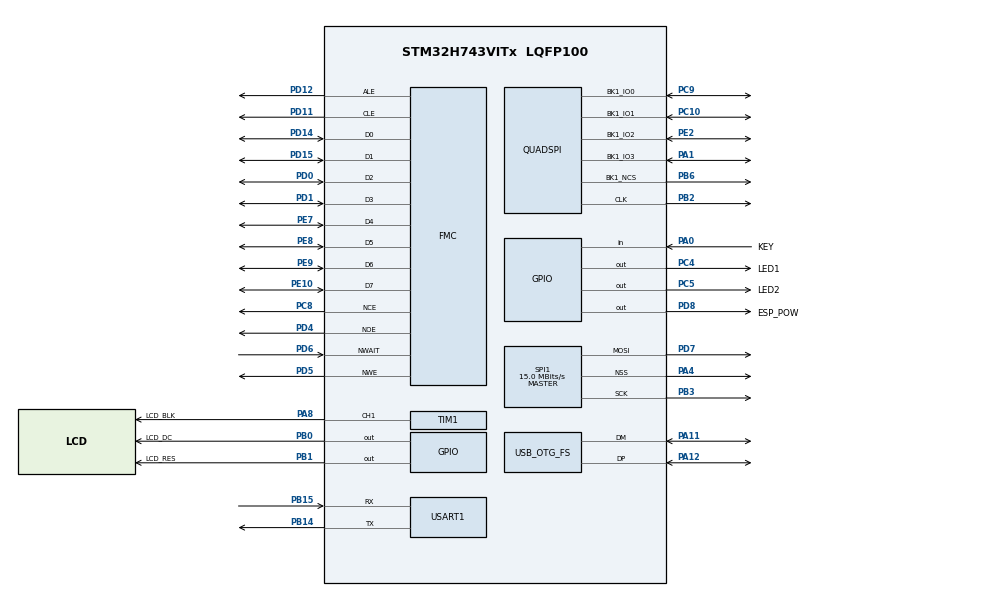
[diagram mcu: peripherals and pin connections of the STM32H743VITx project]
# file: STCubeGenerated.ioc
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CRC.InputDataFormat=CRC_INPUTDATA_FORMAT_WORDS
Dma.Request0=USART1_RX
Dma.Request1=USART1_TX
Dma.Request2=SPI1_TX
Dma.SPI1_TX.2.Direction=DMA_MEMORY_TO_PERIPH
Dma.SPI1_TX.2.EventEnable=DISABLE
Dma.SPI1_TX.2.FIFOMode=DMA_FIFOMODE_DISABLE
Dma.SPI1_TX.2.Instance=DMA1_Stream0
Dma.SPI1_TX.2.MemDataAlignment=DMA_MDATAALIGN_HALFWORD
Dma.SPI1_TX.2.MemInc=DMA_MINC_ENABLE
Dma.SPI1_TX.2.Mode=DMA_NORMAL
Dma.SPI1_TX.2.PeriphDataAlignment=DMA_PDATAALIGN_HALFWORD
Dma.SPI1_TX.2.PeriphInc=DMA_PINC_DISABLE
Dma.SPI1_TX.2.Polarity=HAL_DMAMUX_REQ_GEN_RISING
Dma.SPI1_TX.2.Priority=DMA_PRIORITY_LOW
Dma.SPI1_TX.2.RequestNumber=1
Dma.SPI1_TX.2.SignalID=NONE
Dma.SPI1_TX.2.SyncEnable=DISABLE
Dma.SPI1_TX.2.SyncPolarity=HAL_DMAMUX_SYNC_NO_EVENT
Dma.SPI1_TX.2.SyncRequestNumber=1
Dma.SPI1_TX.2.SyncSignalID=NONE
Dma.USART1_RX.0.Direction=DMA_PERIPH_TO_MEMORY
Dma.USART1_RX.0.EventEnable=DISABLE
Dma.USART1_RX.0.FIFOMode=DMA_FIFOMODE_DISABLE
Dma.USART1_RX.0.Instance=DMA1_Stream2
Dma.USART1_RX.0.MemDataAlignment=DMA_MDATAALIGN_BYTE
Dma.USART1_RX.0.MemInc=DMA_MINC_ENABLE
Dma.USART1_RX.0.Mode=DMA_CIRCULAR
Dma.USART1_RX.0.PeriphDataAlignment=DMA_PDATAALIGN_BYTE
Dma.USART1_RX.0.PeriphInc=DMA_PINC_DISABLE
Dma.USART1_RX.0.Polarity=HAL_DMAMUX_REQ_GEN_RISING
Dma.USART1_RX.0.Priority=DMA_PRIORITY_LOW
Dma.USART1_RX.0.RequestNumber=1
Dma.USART1_RX.0.SignalID=NONE
Dma.USART1_RX.0.SyncEnable=DISABLE
Dma.USART1_RX.0.SyncPolarity=HAL_DMAMUX_SYNC_NO_EVENT
Dma.USART1_RX.0.SyncRequestNumber=1
Dma.USART1_RX.0.SyncSignalID=NONE
Dma.USART1_TX.1.Direction=DMA_MEMORY_TO_PERIPH
Dma.USART1_TX.1.EventEnable=DISABLE
Dma.USART1_TX.1.FIFOMode=DMA_FIFOMODE_DISABLE
Dma.USART1_TX.1.Instance=DMA1_Stream1
Dma.USART1_TX.1.MemDataAlignment=DMA_MDATAALIGN_BYTE
Dma.USART1_TX.1.MemInc=DMA_MINC_ENABLE
Dma.USART1_TX.1.Mode=DMA_NORMAL
Dma.USART1_TX.1.PeriphDataAlignment=DMA_PDATAALIGN_BYTE
Dma.USART1_TX.1.PeriphInc=DMA_PINC_DISABLE
Dma.USART1_TX.1.Polarity=HAL_DMAMUX_REQ_GEN_RISING
Dma.USART1_TX.1.Priority=DMA_PRIORITY_LOW
Dma.USART1_TX.1.RequestNumber=1
Dma.USART1_TX.1.SignalID=NONE
Dma.USART1_TX.1.SyncEnable=DISABLE
Dma.USART1_TX.1.SyncPolarity=HAL_DMAMUX_SYNC_NO_EVENT
Dma.USART1_TX.1.SyncRequestNumber=1
Dma.USART1_TX.1.SyncSignalID=NONE
FMC.AttributeSpaceHiZSetupTime1=3
FMC.AttributeSpaceHoldSetupTime1=2
FMC.AttributeSpaceSetupTime1=3
FMC.AttributeSpaceWaitSetupTime1=3
FMC.CommonSpaceHiZSetupTime1=3
FMC.CommonSpaceHoldSetupTime1=2
FMC.CommonSpaceSetupTime1=3
FMC.CommonSpaceWaitSetupTime1=3
FMC.ECCPageSize1=FMC_NAND_ECC_PAGE_SIZE_2048BYTE
FMC.EccComputation1=FMC_NAND_ECC_ENABLE
FMC.NandBlockNbr1=2048
FMC.NandBlockSize1=64
FMC.NandPageSize1=2048
FMC.NandPlaneNbr1=2
FMC.NandPlaneSize1=4096
FMC.NandSpareAreaSize1=64
Mcu.Family=STM32H7
Mcu.Name=STM32H743VITx
Mcu.Package=LQFP100
Mdma.MDMA_Channel0.QUADSPI_FIFO_TH.0.BlockCount=0
Mdma.MDMA_Channel0.QUADSPI_FIFO_TH.0.BlockDataLength=0
Mdma.MDMA_Channel0.QUADSPI_FIFO_TH.0.BufferTransferLength=128
Mdma.MDMA_Channel0.QUADSPI_FIFO_TH.0.CircularMode=MDMA_LINEAR_LIST
Mdma.MDMA_Channel0.QUADSPI_FIFO_TH.0.DataAlignment=MDMA_DATAALIGN_PACKENABLE
Mdma.MDMA_Channel0.QUADSPI_FIFO_TH.0.DestBlockAddressOffset=0
Mdma.MDMA_Channel0.QUADSPI_FIFO_TH.0.DestBurst=MDMA_DEST_BURST_SINGLE
Mdma.MDMA_Channel0.QUADSPI_FIFO_TH.0.DestDataSize=MDMA_DEST_DATASIZE_BYTE
Mdma.MDMA_Channel0.QUADSPI_FIFO_TH.0.DestinationInc=MDMA_DEST_INC_BYTE
Mdma.MDMA_Channel0.QUADSPI_FIFO_TH.0.DstAddress=0
Mdma.MDMA_Channel0.QUADSPI_FIFO_TH.0.Endianness=MDMA_LITTLE_ENDIANNESS_PRESERVE
Mdma.MDMA_Channel0.QUADSPI_FIFO_TH.0.Instance=MDMA_Channel0
Mdma.MDMA_Channel0.QUADSPI_FIFO_TH.0.MaskAddress=0
Mdma.MDMA_Channel0.QUADSPI_FIFO_TH.0.MaskData=0
Mdma.MDMA_Channel0.QUADSPI_FIFO_TH.0.Priority=MDMA_PRIORITY_VERY_HIGH
Mdma.MDMA_Channel0.QUADSPI_FIFO_TH.0.Rank=First
Mdma.MDMA_Channel0.QUADSPI_FIFO_TH.0.SourceBlockAddressOffset=0
Mdma.MDMA_Channel0.QUADSPI_FIFO_TH.0.SourceBurst=MDMA_SOURCE_BURST_SINGLE
Mdma.MDMA_Channel0.QUADSPI_FIFO_TH.0.SourceDataSize=MDMA_SRC_DATASIZE_BYTE
Mdma.MDMA_Channel0.QUADSPI_FIFO_TH.0.SourceInc=MDMA_SRC_INC_BYTE
Mdma.MDMA_Channel0.QUADSPI_FIFO_TH.0.SrcAddress=0
Mdma.MDMA_Channel0.QUADSPI_FIFO_TH.0.TransferTriggerMode=MDMA_BUFFER_TRANSFER
Mdma.MDMA_Channel0.Request0=QUADSPI_FIFO_TH
Mdma.MDMA_Channel0.RequestsNb=1
Mdma.RequestSet0=MDMA_Channel0
Mdma.RequestSetsNb=1
NVIC.DMA1_Stream0_IRQn=true\:0\:0\:false\:false\:true\:false\:true\:true
NVIC.DMA1_Stream1_IRQn=true\:0\:0\:false\:false\:true\:false\:true\:true
NVIC.DMA1_Stream2_IRQn=true\:0\:0\:false\:false\:true\:false\:true\:true
NVIC.MDMA_IRQn=true\:0\:0\:false\:false\:true\:false\:true\:true
NVIC.OTG_FS_IRQn=true\:5\:0\:true\:false\:false\:true\:true\:true
NVIC.PriorityGroup=NVIC_PRIORITYGROUP_4
NVIC.QUADSPI_IRQn=true\:0\:0\:false\:false\:true\:true\:true\:true
NVIC.SPI1_IRQn=true\:0\:0\:false\:false\:true\:true\:true\:true
NVIC.TIM17_IRQn=true\:4\:0\:true\:false\:true\:false\:true\:true
NVIC.TIM8_UP_TIM13_IRQn=true\:0\:0\:false\:false\:true\:true\:true\:true
NVIC.TimeBase=TIM17_IRQn
NVIC.TimeBaseIP=TIM17
NVIC.USART1_IRQn=true\:0\:0\:false\:false\:true\:true\:true\:true
PA0.GPIO_Label=KEY
PA0.GPIO_PuPd=GPIO_PULLDOWN
PA0.Signal=GPIO_Input
PA1.GPIO_Speed=GPIO_SPEED_FREQ_VERY_HIGH
PA1.Mode=Single Bank 1
PA1.Signal=QUADSPI_BK1_IO3
PA11.GPIO_Speed=GPIO_SPEED_FREQ_VERY_HIGH
PA11.Mode=Device_Only
PA11.Signal=USB_OTG_FS_DM
PA12.GPIO_Speed=GPIO_SPEED_FREQ_VERY_HIGH
PA12.Mode=Device_Only
PA12.Signal=USB_OTG_FS_DP
PA13\ (JTMS/SWDIO).Mode=Serial_Wire
PA13\ (JTMS/SWDIO).Signal=DEBUG_JTMS-SWDIO
PA14\ (JTCK/SWCLK).Mode=Serial_Wire
PA14\ (JTCK/SWCLK).Signal=DEBUG_JTCK-SWCLK
PA4.Mode=NSS_Signal_Hard_Output
PA4.Signal=SPI1_NSS
PA8.GPIO_Label=LCD_BLK
PA8.Signal=S_TIM1_CH1
PB0.GPIO_Label=LCD_DC
PB0.GPIO_PuPd=GPIO_NOPULL
PB0.Signal=GPIO_Output
PB1.GPIO_Label=LCD_RES
PB1.Signal=GPIO_Output
PB14.Mode=Asynchronous
PB14.Signal=USART1_TX
PB15.GPIO_PuPd=GPIO_PULLUP
PB15.Mode=Asynchronous
PB15.Signal=USART1_RX
PB2.GPIO_Speed=GPIO_SPEED_FREQ_VERY_HIGH
PB2.Mode=Single Bank 1
PB2.Signal=QUADSPI_CLK
PB3\ (JTDO/TRACESWO).Mode=TX_Only_Simplex_Unidirect_Master
PB3\ (JTDO/TRACESWO).Signal=SPI1_SCK
PB6.GPIO_Speed=GPIO_SPEED_FREQ_VERY_HIGH
PB6.Mode=Single Bank 1
PB6.Signal=QUADSPI_BK1_NCS
PC10.GPIO_Speed=GPIO_SPEED_FREQ_VERY_HIGH
PC10.Mode=Single Bank 1
PC10.Signal=QUADSPI_BK1_IO1
PC14-OSC32_IN\ (OSC32_IN).Mode=LSE-External-Oscillator
PC14-OSC32_IN\ (OSC32_IN).Signal=RCC_OSC32_IN
PC15-OSC32_OUT\ (OSC32_OUT).Mode=LSE-External-Oscillator
PC15-OSC32_OUT\ (OSC32_OUT).Signal=RCC_OSC32_OUT
PC4.GPIO_Label=LED1
PC4.GPIO_PuPd=GPIO_PULLUP
PC4.PinState=GPIO_PIN_SET
PC4.Signal=GPIO_Output
PC5.GPIO_Label=LED2
PC5.GPIO_PuPd=GPIO_PULLUP
PC5.PinState=GPIO_PIN_SET
PC5.Signal=GPIO_Output
PC8.Mode=NandChipSelect3_1
PC8.Signal=FMC_NCE
PC9.GPIO_Speed=GPIO_SPEED_FREQ_VERY_HIGH
PC9.Mode=Single Bank 1
PC9.Signal=QUADSPI_BK1_IO0
PD0.Signal=FMC_D2_DA2
PD1.Signal=FMC_D3_DA3
PD11.Signal=FMC_A16_CLE
PD12.Signal=FMC_A17_ALE
PD14.Signal=FMC_D0_DA0
PD15.Signal=FMC_D1_DA1
PD4.Signal=FMC_NOE
PD5.Signal=FMC_NWE
PD6.GPIO_PuPd=GPIO_PULLUP
PD6.Signal=FMC_NWAIT
PD7.Mode=TX_Only_Simplex_Unidirect_Master
PD7.Signal=SPI1_MOSI
PD8.GPIO_Label=ESP_POW
PD8.GPIO_PuPd=GPIO_PULLDOWN
PD8.Signal=GPIO_Output
PE10.Signal=FMC_D7_DA7
PE2.GPIO_Speed=GPIO_SPEED_FREQ_VERY_HIGH
PE2.Mode=Single Bank 1
PE2.Signal=QUADSPI_BK1_IO2
PE7.Signal=FMC_D4_DA4
PE8.Signal=FMC_D5_DA5
PE9.Signal=FMC_D6_DA6
PH0-OSC_IN\ (PH0).Mode=HSE-External-Oscillator
PH0-OSC_IN\ (PH0).Signal=RCC_OSC_IN
PH1-OSC_OUT\ (PH1).Mode=HSE-External-Oscillator
PH1-OSC_OUT\ (PH1).Signal=RCC_OSC_OUT
ProjectManager.HeapSize=0x800
ProjectManager.StackSize=0x800
ProjectManager.TargetToolchain=MDK-ARM V5
QUADSPI.ClockPrescaler=2-1
QUADSPI.FifoThreshold=32
QUADSPI.FlashSize=24-1
QUADSPI.SampleShifting=QSPI_SAMPLE_SHIFTING_HALFCYCLE
RCC.ADCFreq_Value=120000000
RCC.APB1Freq_Value=100000000
RCC.APB2Freq_Value=100000000
RCC.APB3Freq_Value=100000000
RCC.APB4Freq_Value=100000000
RCC.CortexFreq_Value=400000000
RCC.D1PPRE=RCC_APB3_DIV2
RCC.D2PPRE1=RCC_APB1_DIV2
RCC.D2PPRE2=RCC_APB2_DIV2
RCC.D3PPRE=RCC_APB4_DIV2
RCC.DIVM1=5
RCC.DIVM2=25
RCC.DIVM3=5
RCC.DIVN1=160
RCC.DIVN2=240
RCC.DIVN3=160
RCC.HCLKFreq_Value=200000000
RCC.HPRE=RCC_HCLK_DIV2
RCC.PLLSourceVirtual=RCC_PLLSOURCE_HSE
RCC.SPI123CLockSelection=RCC_SPI123CLKSOURCE_PLL2
RCC.SYSCLKFreq_VALUE=400000000
RCC.SYSCLKSource=RCC_SYSCLKSOURCE_PLLCLK
RCC.USBCLockSelection=RCC_USBCLKSOURCE_HSI48
RCC.USBFreq_Value=48000000
SH.FMC_A16_CLE.0=FMC_CLE,8b-dmux1
SH.FMC_A17_ALE.0=FMC_ALE,8b-dmux1
SH.FMC_D0_DA0.0=FMC_D0,8b-dmux1
SH.FMC_D1_DA1.0=FMC_D1,8b-dmux1
SH.FMC_D2_DA2.0=FMC_D2,8b-dmux1
SH.FMC_D3_DA3.0=FMC_D3,8b-dmux1
SH.FMC_D4_DA4.0=FMC_D4,8b-dmux1
SH.FMC_D5_DA5.0=FMC_D5,8b-dmux1
SH.FMC_D6_DA6.0=FMC_D6,8b-dmux1
SH.FMC_D7_DA7.0=FMC_D7,8b-dmux1
SH.FMC_NOE.0=FMC_NOE,8b-dmux1
SH.FMC_NWAIT.0=FMC_NWAIT,Wait1
SH.FMC_NWE.0=FMC_NWE,8b-dmux1
SH.S_TIM1_CH1.0=TIM1_CH1,PWM Generation1 CH1
SPI1.BaudRatePrescaler=SPI_BAUDRATEPRESCALER_8
SPI1.CalculateBaudRate=15.0 MBits/s
SPI1.DataSize=SPI_DATASIZE_8BIT
SPI1.Direction=SPI_DIRECTION_2LINES_TXONLY
SPI1.Mode=SPI_MODE_MASTER
SPI1.VirtualNSS=VM_NSSHARD
SPI1.VirtualType=VM_MASTER
TIM1.Channel-PWM\ Generation1\ CH1=TIM_CHANNEL_1
TIM1.Period=1000-1
TIM1.Prescaler=20-1
TIM13.Period=1000-1
TIM13.Prescaler=200-1
USART1.VirtualMode-Asynchronous=VM_ASYNC
USB_OTG_FS.VirtualMode=Device_Only
VP_CRC_VS_CRC.Mode=CRC_Activate
VP_SYS_VS_tim17.Mode=TIM17
VP_TIM13_VS_ClockSourceINT.Mode=Enable_Timer
VP_TIM1_VS_ClockSourceINT.Mode=Internal
board=custom

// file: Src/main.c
/* USER CODE BEGIN Header */
/**
  ******************************************************************************
  * @file           : main.c
  * @brief          : Main program body
  ******************************************************************************
  * @attention
  *
  * Copyright (c) 2022 STMicroelectronics.
  * All rights reserved.
  *
  * This software is licensed under terms that can be found in the LICENSE file
  * in the root directory of this software component.
  * If no LICENSE file comes with this software, it is provided AS-IS.
  *
  ******************************************************************************
  */
/* USER CODE END Header */
#include "main.h"
#include "crc.h"
#include "dma.h"
#include "mdma.h"
#include "quadspi.h"
#include "spi.h"
#include "tim.h"
#include "usart.h"
#include "usb_otg.h"
#include "gpio.h"
#include "fmc.h"

/* USER CODE BEGIN Includes */
#include "Freertos_Init.h"
#include "Bsp_ESP8266.h"

/* USER CODE END Includes */

void SystemClock_Config(void);

int main(void)
{

  /* MCU Configuration--------------------------------------------------------*/

  /* Reset of all peripherals, Initializes the Flash interface and the Systick. */
  HAL_Init();

  /* Configure the system clock */
  SystemClock_Config();

  /* Initialize all configured peripherals */
  MX_GPIO_Init();
  MX_DMA_Init();
  MX_MDMA_Init();
  MX_SPI1_Init();
  MX_USART1_UART_Init();
//  MX_QUADSPI_Init();
//  MX_FMC_Init();
  MX_TIM1_Init();
//  MX_USB_OTG_FS_PCD_Init();
  MX_TIM13_Init();
  MX_CRC_Init();
  /* USER CODE BEGIN 2 */

  Freertos_Init();
  /* USER CODE END 2 */

  /* Infinite loop */
  while (1)
  {

  }
}

void SystemClock_Config(void)
{
  RCC_OscInitTypeDef RCC_OscInitStruct = {0};
  RCC_ClkInitTypeDef RCC_ClkInitStruct = {0};

  /** Supply configuration update enable
  */
  HAL_PWREx_ConfigSupply(PWR_LDO_SUPPLY);

  /** Configure the main internal regulator output voltage
  */
  __HAL_PWR_VOLTAGESCALING_CONFIG(PWR_REGULATOR_VOLTAGE_SCALE1);

  while(!__HAL_PWR_GET_FLAG(PWR_FLAG_VOSRDY)) {}

  /** Initializes the RCC Oscillators according to the specified parameters
  * in the RCC_OscInitTypeDef structure.
  */
  RCC_OscInitStruct.OscillatorType = RCC_OSCILLATORTYPE_HSI48|RCC_OSCILLATORTYPE_HSE;
  RCC_OscInitStruct.HSEState = RCC_HSE_ON;
  RCC_OscInitStruct.HSI48State = RCC_HSI48_ON;
  RCC_OscInitStruct.PLL.PLLState = RCC_PLL_ON;
  RCC_OscInitStruct.PLL.PLLSource = RCC_PLLSOURCE_HSE;
  RCC_OscInitStruct.PLL.PLLM = 5;
  RCC_OscInitStruct.PLL.PLLN = 160;
  RCC_OscInitStruct.PLL.PLLP = 2;
  RCC_OscInitStruct.PLL.PLLQ = 2;
  RCC_OscInitStruct.PLL.PLLR = 2;
  RCC_OscInitStruct.PLL.PLLRGE = RCC_PLL1VCIRANGE_2;
  RCC_OscInitStruct.PLL.PLLVCOSEL = RCC_PLL1VCOWIDE;
  RCC_OscInitStruct.PLL.PLLFRACN = 0;
  if (HAL_RCC_OscConfig(&RCC_OscInitStruct) != HAL_OK)
  {
    Error_Handler();
  }

  /** Initializes the CPU, AHB and APB buses clocks
  */
  RCC_ClkInitStruct.ClockType = RCC_CLOCKTYPE_HCLK|RCC_CLOCKTYPE_SYSCLK
                              |RCC_CLOCKTYPE_PCLK1|RCC_CLOCKTYPE_PCLK2
                              |RCC_CLOCKTYPE_D3PCLK1|RCC_CLOCKTYPE_D1PCLK1;
  RCC_ClkInitStruct.SYSCLKSource = RCC_SYSCLKSOURCE_PLLCLK;
  RCC_ClkInitStruct.SYSCLKDivider = RCC_SYSCLK_DIV1;
  RCC_ClkInitStruct.AHBCLKDivider = RCC_HCLK_DIV2;
  RCC_ClkInitStruct.APB3CLKDivider = RCC_APB3_DIV2;
  RCC_ClkInitStruct.APB1CLKDivider = RCC_APB1_DIV2;
  RCC_ClkInitStruct.APB2CLKDivider = RCC_APB2_DIV2;
  RCC_ClkInitStruct.APB4CLKDivider = RCC_APB4_DIV2;

  if (HAL_RCC_ClockConfig(&RCC_ClkInitStruct, FLASH_LATENCY_2) != HAL_OK)
  {
    Error_Handler();
  }
}

void HAL_TIM_PeriodElapsedCallback(TIM_HandleTypeDef *htim)
{
  if (htim->Instance == TIM17) {
    HAL_IncTick();
  }
  /* USER CODE BEGIN Callback 1 */
  if(htim->Instance ==TIM13)
  {
    Bsp_ESP8266_Timer();
  }
  /* USER CODE END Callback 1 */
}

void Error_Handler(void)
{
  __disable_irq();
  while (1)
  {
  }
}
